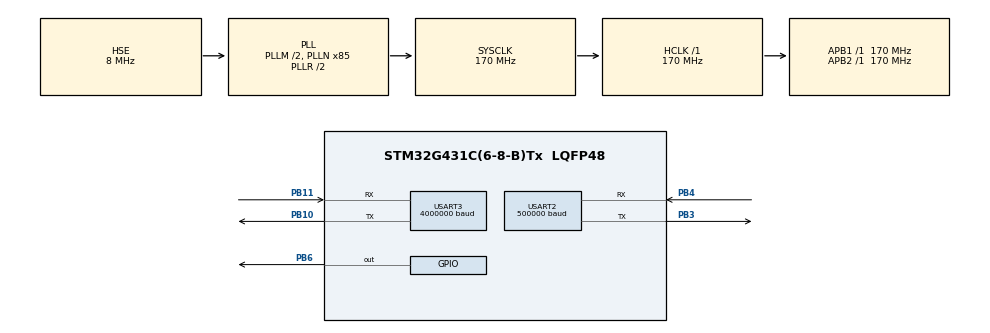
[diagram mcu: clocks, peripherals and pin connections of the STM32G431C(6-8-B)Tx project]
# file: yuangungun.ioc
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Dma.Request0=USART3_RX
Dma.Request1=USART3_TX
Dma.Request2=USART2_RX
Dma.Request3=USART2_TX
Dma.USART2_RX.2.Direction=DMA_PERIPH_TO_MEMORY
Dma.USART2_RX.2.EventEnable=DISABLE
Dma.USART2_RX.2.Instance=DMA1_Channel1
Dma.USART2_RX.2.MemDataAlignment=DMA_MDATAALIGN_BYTE
Dma.USART2_RX.2.MemInc=DMA_MINC_ENABLE
Dma.USART2_RX.2.Mode=DMA_NORMAL
Dma.USART2_RX.2.PeriphDataAlignment=DMA_PDATAALIGN_BYTE
Dma.USART2_RX.2.PeriphInc=DMA_PINC_DISABLE
Dma.USART2_RX.2.Polarity=HAL_DMAMUX_REQ_GEN_RISING
Dma.USART2_RX.2.Priority=DMA_PRIORITY_LOW
Dma.USART2_RX.2.RequestNumber=1
Dma.USART2_RX.2.SignalID=NONE
Dma.USART2_RX.2.SyncEnable=DISABLE
Dma.USART2_RX.2.SyncPolarity=HAL_DMAMUX_SYNC_NO_EVENT
Dma.USART2_RX.2.SyncRequestNumber=1
Dma.USART2_RX.2.SyncSignalID=NONE
Dma.USART2_TX.3.Direction=DMA_MEMORY_TO_PERIPH
Dma.USART2_TX.3.EventEnable=DISABLE
Dma.USART2_TX.3.Instance=DMA1_Channel2
Dma.USART2_TX.3.MemDataAlignment=DMA_MDATAALIGN_BYTE
Dma.USART2_TX.3.MemInc=DMA_MINC_ENABLE
Dma.USART2_TX.3.Mode=DMA_NORMAL
Dma.USART2_TX.3.PeriphDataAlignment=DMA_PDATAALIGN_BYTE
Dma.USART2_TX.3.PeriphInc=DMA_PINC_DISABLE
Dma.USART2_TX.3.Polarity=HAL_DMAMUX_REQ_GEN_RISING
Dma.USART2_TX.3.Priority=DMA_PRIORITY_LOW
Dma.USART2_TX.3.RequestNumber=1
Dma.USART2_TX.3.SignalID=NONE
Dma.USART2_TX.3.SyncEnable=DISABLE
Dma.USART2_TX.3.SyncPolarity=HAL_DMAMUX_SYNC_NO_EVENT
Dma.USART2_TX.3.SyncRequestNumber=1
Dma.USART2_TX.3.SyncSignalID=NONE
Dma.USART3_RX.0.Direction=DMA_PERIPH_TO_MEMORY
Dma.USART3_RX.0.EventEnable=DISABLE
Dma.USART3_RX.0.Instance=DMA1_Channel3
Dma.USART3_RX.0.MemDataAlignment=DMA_MDATAALIGN_BYTE
Dma.USART3_RX.0.MemInc=DMA_MINC_ENABLE
Dma.USART3_RX.0.Mode=DMA_NORMAL
Dma.USART3_RX.0.PeriphDataAlignment=DMA_PDATAALIGN_BYTE
Dma.USART3_RX.0.PeriphInc=DMA_PINC_DISABLE
Dma.USART3_RX.0.Polarity=HAL_DMAMUX_REQ_GEN_RISING
Dma.USART3_RX.0.Priority=DMA_PRIORITY_VERY_HIGH
Dma.USART3_RX.0.RequestNumber=1
Dma.USART3_RX.0.SignalID=NONE
Dma.USART3_RX.0.SyncEnable=DISABLE
Dma.USART3_RX.0.SyncPolarity=HAL_DMAMUX_SYNC_NO_EVENT
Dma.USART3_RX.0.SyncRequestNumber=1
Dma.USART3_RX.0.SyncSignalID=NONE
Dma.USART3_TX.1.Direction=DMA_MEMORY_TO_PERIPH
Dma.USART3_TX.1.EventEnable=DISABLE
Dma.USART3_TX.1.Instance=DMA1_Channel4
Dma.USART3_TX.1.MemDataAlignment=DMA_MDATAALIGN_BYTE
Dma.USART3_TX.1.MemInc=DMA_MINC_ENABLE
Dma.USART3_TX.1.Mode=DMA_NORMAL
Dma.USART3_TX.1.PeriphDataAlignment=DMA_PDATAALIGN_BYTE
Dma.USART3_TX.1.PeriphInc=DMA_PINC_DISABLE
Dma.USART3_TX.1.Polarity=HAL_DMAMUX_REQ_GEN_RISING
Dma.USART3_TX.1.Priority=DMA_PRIORITY_LOW
Dma.USART3_TX.1.RequestNumber=1
Dma.USART3_TX.1.SignalID=NONE
Dma.USART3_TX.1.SyncEnable=DISABLE
Dma.USART3_TX.1.SyncPolarity=HAL_DMAMUX_SYNC_NO_EVENT
Dma.USART3_TX.1.SyncRequestNumber=1
Dma.USART3_TX.1.SyncSignalID=NONE
FREERTOS.BinarySemaphores01=RS485RX,Dynamic,NULL,Available
FREERTOS.Tasks01=zhuhanshu,8,256,StartDefaultTask,Default,NULL,Dynamic,NULL,NULL;RS485,16,128,StartTask02,Default,NULL,Dynamic,NULL,NULL
Mcu.Family=STM32G4
Mcu.Name=STM32G431C(6-8-B)Tx
Mcu.Package=LQFP48
NVIC.DMA1_Channel1_IRQn=true\:5\:0\:false\:false\:true\:true\:false\:true\:true
NVIC.DMA1_Channel2_IRQn=true\:5\:0\:false\:false\:true\:true\:false\:true\:true
NVIC.DMA1_Channel3_IRQn=true\:5\:0\:false\:false\:true\:true\:false\:true\:true
NVIC.DMA1_Channel4_IRQn=true\:5\:0\:false\:false\:true\:true\:false\:true\:true
NVIC.PriorityGroup=NVIC_PRIORITYGROUP_4
NVIC.TIM8_UP_IRQn=true\:15\:0\:false\:false\:true\:false\:false\:true\:true
NVIC.TimeBase=TIM8_UP_IRQn
NVIC.TimeBaseIP=TIM8
NVIC.USART2_IRQn=true\:5\:0\:false\:false\:true\:true\:true\:true\:true
NVIC.USART3_IRQn=true\:5\:0\:false\:false\:true\:true\:false\:true\:true
PA13.Mode=Serial_Wire
PA13.Signal=SYS_JTMS-SWDIO
PA14.Mode=Serial_Wire
PA14.Signal=SYS_JTCK-SWCLK
PB10.Mode=Asynchronous
PB10.Signal=USART3_TX
PB11.Mode=Asynchronous
PB11.Signal=USART3_RX
PB3.Mode=Asynchronous
PB3.Signal=USART2_TX
PB4.Mode=Asynchronous
PB4.Signal=USART2_RX
PB6.Signal=GPIO_Output
PF0-OSC_IN.Mode=HSE-External-Oscillator
PF0-OSC_IN.Signal=RCC_OSC_IN
PF1-OSC_OUT.Mode=HSE-External-Oscillator
PF1-OSC_OUT.Signal=RCC_OSC_OUT
ProjectManager.HeapSize=0x200
ProjectManager.StackSize=0x400
ProjectManager.TargetToolchain=MDK-ARM V5.32
RCC.ADC12Freq_Value=170000000
RCC.AHBFreq_Value=170000000
RCC.APB1Freq_Value=170000000
RCC.APB1TimFreq_Value=170000000
RCC.APB2Freq_Value=170000000
RCC.APB2TimFreq_Value=170000000
RCC.CortexFreq_Value=170000000
RCC.EXTERNAL_CLOCK_VALUE=12288000
RCC.HCLKFreq_Value=170000000
RCC.HSE_VALUE=8000000
RCC.HSI48_VALUE=48000000
RCC.HSI_VALUE=16000000
RCC.LSE_VALUE=32768
RCC.PLLM=RCC_PLLM_DIV2
RCC.PLLN=85
RCC.PLLSourceVirtual=RCC_PLLSOURCE_HSE
RCC.SYSCLKFreq_VALUE=170000000
RCC.SYSCLKSource=RCC_SYSCLKSOURCE_PLLCLK
RCC.USBFreq_Value=170000000
RCC.VCOOutputFreq_Value=340000000
TIM2.Prescaler=169
USART2.BaudRate=500000
USART2.VirtualMode-Asynchronous=VM_ASYNC
USART3.BaudRate=4000000
USART3.VirtualMode-Asynchronous=VM_ASYNC
VP_FREERTOS_VS_CMSIS_V2.Mode=CMSIS_V2
VP_SYS_VS_DBSignals.Mode=DisableDeadBatterySignals
VP_SYS_VS_tim8.Mode=TIM8
VP_TIM2_VS_ClockSourceINT.Mode=Internal
board=custom

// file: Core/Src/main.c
/* USER CODE BEGIN Header */
/**
  ******************************************************************************
  * @file           : main.c
  * @brief          : Main program body
  ******************************************************************************
  * @attention
  *
  * Copyright (c) 2025 STMicroelectronics.
  * All rights reserved.
  *
  * This software is licensed under terms that can be found in the LICENSE file
  * in the root directory of this software component.
  * If no LICENSE file comes with this software, it is provided AS-IS.
  *
  ******************************************************************************
  */
/* USER CODE END Header */
#include "main.h"
#include "cmsis_os.h"
#include "dma.h"
#include "tim.h"
#include "usart.h"
#include "gpio.h"

/* USER CODE BEGIN Includes */
#include  "MYDWT.h"
#include  "RS485.h"
#include  "stdio.h"
/* USER CODE END Includes */

void SystemClock_Config(void);
void MX_FREERTOS_Init(void);

int main(void)
{

  /* MCU Configuration--------------------------------------------------------*/

  /* Reset of all peripherals, Initializes the Flash interface and the Systick. */
  HAL_Init();

  /* Configure the system clock */
  SystemClock_Config();

  /* Initialize all configured peripherals */
  MX_GPIO_Init();
  MX_DMA_Init();
  MX_USART2_UART_Init();
  MX_USART3_UART_Init();
  MX_TIM2_Init();
  /* USER CODE BEGIN 2 */
	RS485_RX_EN
	HAL_TIM_Base_Start(&htim2);
	Enable_DWT_CycleCounter();
  /* USER CODE END 2 */

  /* Init scheduler */
  osKernelInitialize();  /* Call init function for freertos objects (in cmsis_os2.c) */
  MX_FREERTOS_Init();

  /* Start scheduler */
  osKernelStart();

  /* We should never get here as control is now taken by the scheduler */

  /* Infinite loop */
  /* USER CODE BEGIN WHILE */

  while (1)
  {
//		Analyze_RS485_data();
//		send_ACKback(MASTER_ID ,Slave1_ID);
//		HAL_Delay(1000);
//		printf("yuangungun\n");
//		HAL_Delay(1000);
    /* USER CODE END WHILE */

  }
}

void SystemClock_Config(void)
{
  RCC_OscInitTypeDef RCC_OscInitStruct = {0};
  RCC_ClkInitTypeDef RCC_ClkInitStruct = {0};

  /** Configure the main internal regulator output voltage
  */
  HAL_PWREx_ControlVoltageScaling(PWR_REGULATOR_VOLTAGE_SCALE1_BOOST);

  /** Initializes the RCC Oscillators according to the specified parameters
  * in the RCC_OscInitTypeDef structure.
  */
  RCC_OscInitStruct.OscillatorType = RCC_OSCILLATORTYPE_HSE;
  RCC_OscInitStruct.HSEState = RCC_HSE_ON;
  RCC_OscInitStruct.PLL.PLLState = RCC_PLL_ON;
  RCC_OscInitStruct.PLL.PLLSource = RCC_PLLSOURCE_HSE;
  RCC_OscInitStruct.PLL.PLLM = RCC_PLLM_DIV2;
  RCC_OscInitStruct.PLL.PLLN = 85;
  RCC_OscInitStruct.PLL.PLLP = RCC_PLLP_DIV2;
  RCC_OscInitStruct.PLL.PLLQ = RCC_PLLQ_DIV2;
  RCC_OscInitStruct.PLL.PLLR = RCC_PLLR_DIV2;
  if (HAL_RCC_OscConfig(&RCC_OscInitStruct) != HAL_OK)
  {
    Error_Handler();
  }

  /** Initializes the CPU, AHB and APB buses clocks
  */
  RCC_ClkInitStruct.ClockType = RCC_CLOCKTYPE_HCLK|RCC_CLOCKTYPE_SYSCLK
                              |RCC_CLOCKTYPE_PCLK1|RCC_CLOCKTYPE_PCLK2;
  RCC_ClkInitStruct.SYSCLKSource = RCC_SYSCLKSOURCE_PLLCLK;
  RCC_ClkInitStruct.AHBCLKDivider = RCC_SYSCLK_DIV1;
  RCC_ClkInitStruct.APB1CLKDivider = RCC_HCLK_DIV1;
  RCC_ClkInitStruct.APB2CLKDivider = RCC_HCLK_DIV1;

  if (HAL_RCC_ClockConfig(&RCC_ClkInitStruct, FLASH_LATENCY_4) != HAL_OK)
  {
    Error_Handler();
  }
}

void HAL_TIM_PeriodElapsedCallback(TIM_HandleTypeDef *htim)
{
  if (htim->Instance == TIM8)
  {
    HAL_IncTick();
  }
}

void Error_Handler(void)
{
  __disable_irq();
  while (1)
  {
  }
}

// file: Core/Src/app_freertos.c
/* USER CODE BEGIN Header */
/**
  ******************************************************************************
  * File Name          : app_freertos.c
  * Description        : Code for freertos applications
  ******************************************************************************
  * @attention
  *
  * Copyright (c) 2025 STMicroelectronics.
  * All rights reserved.
  *
  * This software is licensed under terms that can be found in the LICENSE file
  * in the root directory of this software component.
  * If no LICENSE file comes with this software, it is provided AS-IS.
  *
  ******************************************************************************
  */
/* USER CODE END Header */

#include "FreeRTOS.h"
#include "task.h"
#include "main.h"
#include "cmsis_os.h"

/* USER CODE BEGIN Includes */
#include  "stdio.h"
#include  "semphr.h"
#include  "tim.h"
#include  "RS485.h"
#include  "MYDWT.h"
/* USER CODE END Includes */

/* USER CODE BEGIN Variables */

//RS485应答   优先级    osPriorityBelowNormal       task02
//zhuhanshu   优先级    osPriorityLow               dautask

/* USER CODE END Variables */
/* Definitions for zhuhanshu */
osThreadId_t zhuhanshuHandle;
const osThreadAttr_t zhuhanshu_attributes = {
  .name = "zhuhanshu",
  .priority = (osPriority_t) osPriorityLow,
  .stack_size = 256 * 4
};
/* Definitions for RS485 */
osThreadId_t RS485Handle;
const osThreadAttr_t RS485_attributes = {
  .name = "RS485",
  .priority = (osPriority_t) osPriorityBelowNormal,
  .stack_size = 128 * 4
};
/* Definitions for RS485RX */
osSemaphoreId_t RS485RXHandle;
const osSemaphoreAttr_t RS485RX_attributes = {
  .name = "RS485RX"
};

void StartDefaultTask(void *argument);
void StartTask02(void *argument);

void MX_FREERTOS_Init(void); /* (MISRA C 2004 rule 8.1) */

void MX_FREERTOS_Init(void) {

  /* Create the semaphores(s) */
  /* creation of RS485RX */
  RS485RXHandle = osSemaphoreNew(1, 1, &RS485RX_attributes);

  /* Create the thread(s) */
  /* creation of zhuhanshu */
  zhuhanshuHandle = osThreadNew(StartDefaultTask, NULL, &zhuhanshu_attributes);

  /* creation of RS485 */
  RS485Handle = osThreadNew(StartTask02, NULL, &RS485_attributes);

}

void StartDefaultTask(void *argument)
{
  /* USER CODE BEGIN StartDefaultTask */
  /* Infinite loop */
  for(;;)
  {
//		printf("jiji\n");
    osDelay(1);
  }
  /* USER CODE END StartDefaultTask */
}

/* USER CODE BEGIN Header_StartTask02 */
/**0
* @brief Function implementing the RS485 thread.
* @param argument: Not used
* @retval None
*/
/* USER CODE END Header_StartTask02 */
void StartTask02(void *argument)
{
  /* USER CODE BEGIN StartTask02 */
  /* Infinite loop */
  for(;;)
  {

     if(xSemaphoreTake(RS485RXHandle, portMAX_DELAY) == pdPASS )  //没有信号量我就把自己挂起来，让其他函数执行
    {

			Analyze_RS485_data();
//			end_cycle = DWT->CYCCNT;
//			printf("%lld\n", end_cycle - start_cycle);
    }
  }
  /* USER CODE END StartTask02 */
}
